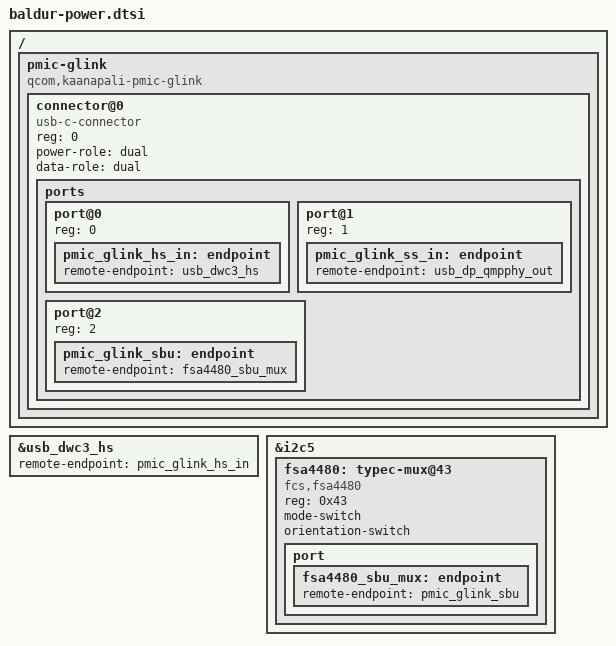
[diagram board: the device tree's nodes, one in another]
// SPDX-License-Identifier: BSD-3-Clause
/*
 * TB323FU ("baldur"): battery and Type-C over pmic-glink, on the charger
 * firmware's PMIC_RTR_SOCCP_APPS channel (SoCCP).
 *
 * The vendor tree has two usb-c-connectors under ucsi-glink: connector@0 /
 * ucsi port0 is the bottom port (USB 3.2 + DP), ucsi port1 the side port
 * (USB 2.0 only). Only connector@0 is wired here: HS to the dwc3 (data role
 * from ucsi) and SS to the QMP PHY (orientation from the firmware). The
 * vendor ucsi-glink "gpios" (TLMM 30) is not an orientation input but the HS
 * port select (low = bottom, high = side).
 */

/ {
	pmic-glink {
		compatible = "qcom,kaanapali-pmic-glink";
		#address-cells = <1>;
		#size-cells = <0>;

		connector@0 {
			compatible = "usb-c-connector";
			reg = <0>;

			power-role = "dual";
			data-role = "dual";

			ports {
				#address-cells = <1>;
				#size-cells = <0>;

				port@0 {
					reg = <0>;

					pmic_glink_hs_in: endpoint {
						remote-endpoint = <&usb_dwc3_hs>;
					};
				};

				port@1 {
					reg = <1>;

					pmic_glink_ss_in: endpoint {
						remote-endpoint = <&usb_dp_qmpphy_out>;
					};
				};

				port@2 {
					reg = <2>;

					pmic_glink_sbu: endpoint {
						remote-endpoint = <&fsa4480_sbu_mux>;
					};
				};
			};
		};
	};
};

&usb_dwc3_hs {
	remote-endpoint = <&pmic_glink_hs_in>;
};

/*
 * USB-C analog audio / SBU: the bottom port's SBU switch is the
 * FSA4480 at i2c5 0x43 (vendor "fsa4480_i2c", into ucsi connector 0); the
 * side port's is 0x42 ("fsa4480_sub_i2c", connector 1 -- not wired, that
 * port has no connector node here). No supply in the vendor node.
 */
&i2c5 {
	status = "okay";

	fsa4480: typec-mux@43 {
		compatible = "fcs,fsa4480";
		reg = <0x43>;

		mode-switch;
		orientation-switch;

		port {
			fsa4480_sbu_mux: endpoint {
				remote-endpoint = <&pmic_glink_sbu>;
			};
		};
	};
};
